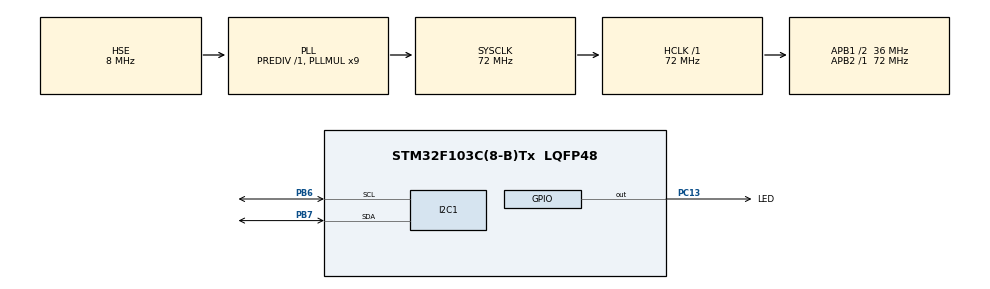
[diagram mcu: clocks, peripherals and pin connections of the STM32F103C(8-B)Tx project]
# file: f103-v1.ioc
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I2C1.I2C_Mode=I2C_Fast
Mcu.Family=STM32F1
Mcu.Name=STM32F103C(8-B)Tx
Mcu.Package=LQFP48
NVIC.PriorityGroup=NVIC_PRIORITYGROUP_4
PA13.Mode=Serial_Wire
PA13.Signal=SYS_JTMS-SWDIO
PA14.Mode=Serial_Wire
PA14.Signal=SYS_JTCK-SWCLK
PB6.Mode=I2C
PB6.Signal=I2C1_SCL
PB7.Mode=I2C
PB7.Signal=I2C1_SDA
PC13-TAMPER-RTC.GPIO_Label=LED
PC13-TAMPER-RTC.Signal=GPIO_Output
PD0-OSC_IN.Mode=HSE-External-Oscillator
PD0-OSC_IN.Signal=RCC_OSC_IN
PD1-OSC_OUT.Mode=HSE-External-Oscillator
PD1-OSC_OUT.Signal=RCC_OSC_OUT
ProjectManager.HeapSize=0x200
ProjectManager.StackSize=0x400
ProjectManager.TargetToolchain=Other Toolchains (GPDSC)
RCC.AHBFreq_Value=72000000
RCC.APB1CLKDivider=RCC_HCLK_DIV2
RCC.APB1Freq_Value=36000000
RCC.APB1TimFreq_Value=72000000
RCC.APB2Freq_Value=72000000
RCC.APB2TimFreq_Value=72000000
RCC.HCLKFreq_Value=72000000
RCC.PLLMUL=RCC_PLL_MUL9
RCC.PLLSourceVirtual=RCC_PLLSOURCE_HSE
RCC.SYSCLKFreq_VALUE=72000000
RCC.SYSCLKSource=RCC_SYSCLKSOURCE_PLLCLK
RCC.USBFreq_Value=72000000
board=custom

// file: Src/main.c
/* USER CODE BEGIN Header */
/**
  ******************************************************************************
  * @file           : main.c
  * @brief          : Main program body
  ******************************************************************************
  * @attention
  *
  * <h2><center>&copy; Copyright (c) 2019 STMicroelectronics.
  * All rights reserved.</center></h2>
  *
  * This software component is licensed by ST under BSD 3-Clause license,
  * the "License"; You may not use this file except in compliance with the
  * License. You may obtain a copy of the License at:
  *                        opensource.org/licenses/BSD-3-Clause
  *
  ******************************************************************************
  */
/* USER CODE END Header */

#include "main.h"
#include "i2c.h"
#include "gpio.h"

/* USER CODE BEGIN Includes */
#include "ssd1306.h"
#include "fonts.h"
/* USER CODE END Includes */

void SystemClock_Config(void);
/* USER CODE BEGIN PFP */
void HAL_I2C_ClearBusyFlagErrata_2_14_7(I2C_HandleTypeDef *hi2c);
/* USER CODE END PFP */

int main(void)
{

	/* MCU Configuration--------------------------------------------------------*/

	/* Reset of all peripherals, Initializes the Flash interface and the Systick. */
	HAL_Init();

	/* Configure the system clock */
	SystemClock_Config();

	/* Initialize all configured peripherals */
	MX_GPIO_Init();
	MX_I2C1_Init();
	/* USER CODE BEGIN 2 */
	//HAL_I2C_ClearBusyFlagErrata_2_14_7(&hi2c1);
	HAL_Delay(1000);
	//uint8_t buf[3] = { 0x10, 0x11, 0x12 };
	/* USER CODE END 2 */

	/* Infinite loop */
	while (1)
	{

		/* USER CODE BEGIN 3 */
		//HAL_StatusTypeDef status = HAL_I2C_Master_Transmit(&hi2c1, 0x3C, buf, 3, 5000);
		HAL_Delay(1000);

		SSD1306_Init();   // initialize the diaply

		SSD1306_GotoXY(10, 10);  // goto 10, 10
		SSD1306_Puts("HELLO", &Font_11x18, 1);  // print Hello
		SSD1306_GotoXY(10, 30);
			  SSD1306_Puts("WORLD !!", &Font_11x18, 1);
			  SSD1306_UpdateScreen();  // update screen
	}
	/* USER CODE END 3 */
}

void SystemClock_Config(void)
{
	RCC_OscInitTypeDef RCC_OscInitStruct = { 0 };
	RCC_ClkInitTypeDef RCC_ClkInitStruct = { 0 };

	/** Initializes the CPU, AHB and APB busses clocks
	*/
	RCC_OscInitStruct.OscillatorType = RCC_OSCILLATORTYPE_HSE;
	RCC_OscInitStruct.HSEState = RCC_HSE_ON;
	RCC_OscInitStruct.HSEPredivValue = RCC_HSE_PREDIV_DIV1;
	RCC_OscInitStruct.HSIState = RCC_HSI_ON;
	RCC_OscInitStruct.PLL.PLLState = RCC_PLL_ON;
	RCC_OscInitStruct.PLL.PLLSource = RCC_PLLSOURCE_HSE;
	RCC_OscInitStruct.PLL.PLLMUL = RCC_PLL_MUL9;
	if (HAL_RCC_OscConfig(&RCC_OscInitStruct) != HAL_OK)
	{
		Error_Handler();
	}
	/** Initializes the CPU, AHB and APB busses clocks
	*/
	RCC_ClkInitStruct.ClockType = RCC_CLOCKTYPE_HCLK | RCC_CLOCKTYPE_SYSCLK
	                            | RCC_CLOCKTYPE_PCLK1 | RCC_CLOCKTYPE_PCLK2;
	RCC_ClkInitStruct.SYSCLKSource = RCC_SYSCLKSOURCE_PLLCLK;
	RCC_ClkInitStruct.AHBCLKDivider = RCC_SYSCLK_DIV1;
	RCC_ClkInitStruct.APB1CLKDivider = RCC_HCLK_DIV2;
	RCC_ClkInitStruct.APB2CLKDivider = RCC_HCLK_DIV1;

	if (HAL_RCC_ClockConfig(&RCC_ClkInitStruct, FLASH_LATENCY_2) != HAL_OK)
	{
		Error_Handler();
	}
}

/* USER CODE BEGIN 4 */
void HAL_I2C_ClearBusyFlagErrata_2_14_7(I2C_HandleTypeDef *hi2c) {

	static uint8_t resetTried = 0;
	if (resetTried == 1) {
		return ;
	}
	uint32_t SDA_PIN = GPIO_PIN_7;
	uint32_t SCL_PIN = GPIO_PIN_6;
	GPIO_InitTypeDef GPIO_InitStruct;

	// 1
	__HAL_I2C_DISABLE(hi2c);

	// 2
	GPIO_InitStruct.Pin = SDA_PIN | SCL_PIN;
	GPIO_InitStruct.Mode = GPIO_MODE_OUTPUT_OD;
	GPIO_InitStruct.Pull = GPIO_NOPULL;
	GPIO_InitStruct.Speed = GPIO_SPEED_FREQ_HIGH;
	HAL_GPIO_Init(GPIOB, &GPIO_InitStruct);

	P_HAL_GPIO_WRITE_ODR(GPIOB, SDA_PIN);
	P_HAL_GPIO_WRITE_ODR(GPIOB, SCL_PIN);

	// 3
	GPIO_PinState pinState;
	if (HAL_GPIO_ReadPin(GPIOB, SDA_PIN) == GPIO_PIN_RESET) {
		for (;;) {}
	}
	if (HAL_GPIO_ReadPin(GPIOB, SCL_PIN) == GPIO_PIN_RESET) {
		for (;;) {}
	}

	// 4
	GPIO_InitStruct.Pin = SDA_PIN;
	HAL_GPIO_Init(GPIOB, &GPIO_InitStruct);

	HAL_GPIO_TogglePin(GPIOB, SDA_PIN);

	// 5
	if(HAL_GPIO_ReadPin(GPIOB, SDA_PIN) == GPIO_PIN_SET) {
		for (;;) {}
	}

	// 6
	GPIO_InitStruct.Pin = SCL_PIN;
	HAL_GPIO_Init(GPIOB, &GPIO_InitStruct);

	HAL_GPIO_TogglePin(GPIOB, SCL_PIN);

	// 7
	if(HAL_GPIO_ReadPin(GPIOB, SCL_PIN) == GPIO_PIN_SET) {
		for (;;) {}
	}

	// 8
	GPIO_InitStruct.Pin = SDA_PIN;
	HAL_GPIO_Init(GPIOB, &GPIO_InitStruct);

	P_HAL_GPIO_WRITE_ODR(GPIOB, SDA_PIN);

	// 9
	if(HAL_GPIO_ReadPin(GPIOB, SDA_PIN) == GPIO_PIN_RESET) {
		for (;;) {}
	}

	// 10
	GPIO_InitStruct.Pin = SCL_PIN;
	HAL_GPIO_Init(GPIOB, &GPIO_InitStruct);

	P_HAL_GPIO_WRITE_ODR(GPIOB, SCL_PIN);

	// 11
	if(HAL_GPIO_ReadPin(GPIOB, SCL_PIN) == GPIO_PIN_RESET) {
		for (;;) {}
	}

	// 12
	GPIO_InitStruct.Pin = SDA_PIN | SCL_PIN;
	GPIO_InitStruct.Mode = GPIO_MODE_AF_OD;
	GPIO_InitStruct.Speed = GPIO_MODE_AF_OD;
	HAL_GPIO_Init(GPIOB, &GPIO_InitStruct);

	// 13
	hi2c->Instance->CR1 |= I2C_CR1_SWRST;

	// 14
	hi2c->Instance->CR1 ^= I2C_CR1_SWRST;

	// 15
	__HAL_I2C_ENABLE(hi2c);

	resetTried = 1;
}

void P_HAL_GPIO_WRITE_ODR(GPIO_TypeDef* GPIOx, uint16_t GPIO_Pin)
{
	/* Check the parameters */
	assert_param(IS_GPIO_PIN(GPIO_Pin));

	GPIOx->ODR |= GPIO_Pin;
}

/* USER CODE END 4 */

void Error_Handler(void)
{
}

/************************ (C) COPYRIGHT STMicroelectronics *****END OF FILE****/
